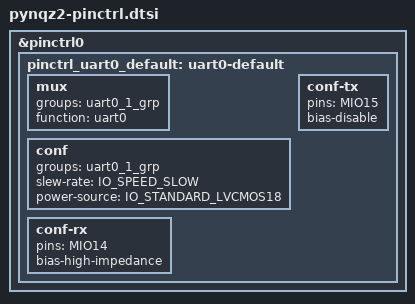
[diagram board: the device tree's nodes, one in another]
/*
 * Copyright (c) 2022 Henrik Brix Andersen <henrik@brixandersen.dk>
 *
 * SPDX-License-Identifier: Apache-2.0
 */

#include <zephyr/dt-bindings/pinctrl/pinctrl-zynq.h>

&pinctrl0 {
	pinctrl_uart0_default: uart0-default {
		mux {
			groups = "uart0_1_grp";
			function = "uart0";
		};

		conf {
			groups = "uart0_1_grp";
			slew-rate = <IO_SPEED_SLOW>;
			power-source = <IO_STANDARD_LVCMOS18>;
		};

		conf-rx {
			pins = "MIO14";
			bias-high-impedance;
		};

		conf-tx {
			pins = "MIO15";
			bias-disable;
		};
	};
};
